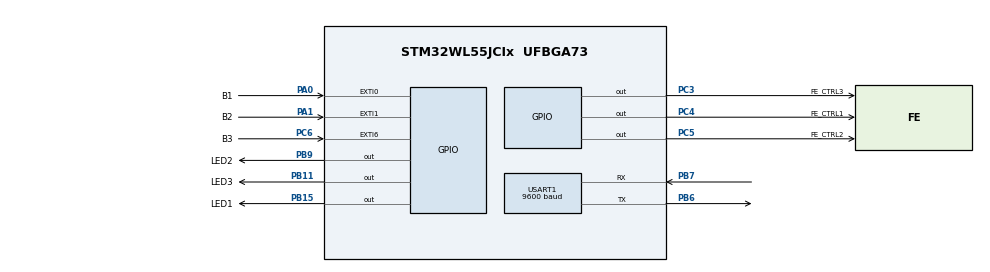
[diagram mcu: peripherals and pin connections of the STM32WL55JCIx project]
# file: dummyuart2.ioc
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Mcu.Family=STM32WL
Mcu.Name=STM32WL55JCIx
Mcu.Package=UFBGA73
NVIC.PriorityGroup=NVIC_PRIORITYGROUP_4
NVIC.USART1_IRQn=true\:0\:0\:false\:false\:true\:true\:true\:true
PA0.GPIO_Label=B1
PA0.GPIO_ModeDefaultEXTI=GPIO_MODE_IT_FALLING
PA0.GPIO_PuPd=GPIO_PULLUP
PA0.Signal=GPXTI0
PA1.GPIO_Label=B2
PA1.GPIO_ModeDefaultEXTI=GPIO_MODE_IT_FALLING
PA1.GPIO_PuPd=GPIO_PULLUP
PA1.Signal=GPXTI1
PA2.GPIO_Label=T_VCP_RX
PA2.Signal=USART2_TX
PA3.GPIO_Label=T_VCP_RX
PA3.Signal=USART2_RX
PB11.GPIO_Label=LED3
PB11.GPIO_Speed=GPIO_SPEED_FREQ_HIGH
PB11.Signal=GPIO_Output
PB15.GPIO_Label=LED1
PB15.GPIO_Speed=GPIO_SPEED_FREQ_HIGH
PB15.Signal=GPIO_Output
PB6.GPIO_ModeDefaultPP=GPIO_MODE_AF_OD
PB6.Mode=Asynchronous
PB6.Signal=USART1_TX
PB7.GPIO_ModeDefaultPP=GPIO_MODE_AF_OD
PB7.Mode=Asynchronous
PB7.Signal=USART1_RX
PB9.GPIO_FM9=__NULL
PB9.GPIO_Label=LED2
PB9.GPIO_Speed=GPIO_SPEED_FREQ_HIGH
PB9.Signal=GPIO_Output
PC14-OSC32_IN.Signal=RCC_OSC32_IN
PC15-OSC32_OUT.Signal=RCC_OSC32_OUT
PC3.GPIO_Label=FE_CTRL3
PC3.GPIO_Speed=GPIO_SPEED_FREQ_VERY_HIGH
PC3.Signal=GPIO_Output
PC4.GPIO_Label=FE_CTRL1
PC4.GPIO_Speed=GPIO_SPEED_FREQ_VERY_HIGH
PC4.Signal=GPIO_Output
PC5.GPIO_Label=FE_CTRL2
PC5.GPIO_Speed=GPIO_SPEED_FREQ_VERY_HIGH
PC5.Signal=GPIO_Output
PC6.GPIO_Label=B3
PC6.GPIO_ModeDefaultEXTI=GPIO_MODE_IT_FALLING
PC6.GPIO_PuPd=GPIO_PULLUP
PC6.Signal=GPXTI6
ProjectManager.HeapSize=0x200
ProjectManager.StackSize=0x400
ProjectManager.TargetToolchain=STM32CubeIDE
RCC.AHBFreq_Value=32000000
RCC.APB1Freq_Value=32000000
RCC.APB1TimFreq_Value=32000000
RCC.APB2Freq_Value=32000000
RCC.APB2TimFreq_Value=32000000
RCC.APB3Freq_Value=32000000
RCC.CortexFreq_Value=32000000
RCC.HCLKFreq_Value=32000000
RCC.HSE_VALUE=32000000
RCC.HSI_VALUE=16000000
RCC.LSE_VALUE=32768
RCC.MSIClockRange=RCC_MSIRANGE_10
RCC.SYSCLKFreq_VALUE=32000000
RCC.VCOOutputFreq_Value=256000000
USART1.BaudRate=9600
USART1.OneBitSampling=UART_ONE_BIT_SAMPLE_ENABLE
USART1.VirtualMode-Asynchronous=VM_ASYNC
board=NUCLEO-WL55JC2

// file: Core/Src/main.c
/* USER CODE BEGIN Header */
/**
  ******************************************************************************
  * @file           : main.c
  * @brief          : Main program body
  ******************************************************************************
  * @attention
  *
  * Copyright (c) 2022 STMicroelectronics.
  * All rights reserved.
  *
  * This software is licensed under terms that can be found in the LICENSE file
  * in the root directory of this software component.
  * If no LICENSE file comes with this software, it is provided AS-IS.
  *
  ******************************************************************************
  */
/* USER CODE END Header */
#include "main.h"

 UART_HandleTypeDef huart1;

void SystemClock_Config(void);
static void MX_GPIO_Init(void);
static void MX_USART1_UART_Init(void);

/* USER CODE BEGIN 0 */
uint8_t dummymsg[10]={
		 1,2,3,4,5,6,7,8,9,10
 };

uint8_t rxdata[10] = {0};
/* USER CODE END 0 */

int main(void)
{

  /* MCU Configuration--------------------------------------------------------*/

  /* Reset of all peripherals, Initializes the Flash interface and the Systick. */
  HAL_Init();

  /* Configure the system clock */
  SystemClock_Config();

  /* Initialize all configured peripherals */
  MX_GPIO_Init();
  MX_USART1_UART_Init();

  /* Infinite loop */
  while (1)
  {

    /* USER CODE BEGIN 3 */
	 // HAL_UART_Receive_IT(&huart1, rxdata, 10);
	  HAL_GPIO_WritePin(LED2_GPIO_Port, LED2_Pin, GPIO_PIN_SET);
	  HAL_UART_Transmit(&huart1, (uint8_t *)dummymsg, 10, 100);
	  HAL_GPIO_WritePin(LED2_GPIO_Port, LED2_Pin, GPIO_PIN_RESET);
  /* USER CODE END 3 */
}
}

void SystemClock_Config(void)
{
  RCC_OscInitTypeDef RCC_OscInitStruct = {0};
  RCC_ClkInitTypeDef RCC_ClkInitStruct = {0};

  /** Configure the main internal regulator output voltage
  */
  __HAL_PWR_VOLTAGESCALING_CONFIG(PWR_REGULATOR_VOLTAGE_SCALE1);

  /** Initializes the CPU, AHB and APB busses clocks
  */
  RCC_OscInitStruct.OscillatorType = RCC_OSCILLATORTYPE_MSI;
  RCC_OscInitStruct.MSIState = RCC_MSI_ON;
  RCC_OscInitStruct.MSICalibrationValue = RCC_MSICALIBRATION_DEFAULT;
  RCC_OscInitStruct.MSIClockRange = RCC_MSIRANGE_10;
  RCC_OscInitStruct.PLL.PLLState = RCC_PLL_NONE;
  if (HAL_RCC_OscConfig(&RCC_OscInitStruct) != HAL_OK)
  {
    Error_Handler();
  }

  /** Configure the SYSCLKSource, HCLK, PCLK1 and PCLK2 clocks dividers
  */
  RCC_ClkInitStruct.ClockType = RCC_CLOCKTYPE_HCLK3|RCC_CLOCKTYPE_HCLK
                              |RCC_CLOCKTYPE_SYSCLK|RCC_CLOCKTYPE_PCLK1
                              |RCC_CLOCKTYPE_PCLK2;
  RCC_ClkInitStruct.SYSCLKSource = RCC_SYSCLKSOURCE_MSI;
  RCC_ClkInitStruct.AHBCLKDivider = RCC_SYSCLK_DIV1;
  RCC_ClkInitStruct.APB1CLKDivider = RCC_HCLK_DIV1;
  RCC_ClkInitStruct.APB2CLKDivider = RCC_HCLK_DIV1;
  RCC_ClkInitStruct.AHBCLK3Divider = RCC_SYSCLK_DIV1;

  if (HAL_RCC_ClockConfig(&RCC_ClkInitStruct, FLASH_LATENCY_1) != HAL_OK)
  {
    Error_Handler();
  }
}

static void MX_USART1_UART_Init(void)
{

  huart1.Instance = USART1;
  huart1.Init.BaudRate = 9600;
  huart1.Init.WordLength = UART_WORDLENGTH_8B;
  huart1.Init.StopBits = UART_STOPBITS_1;
  huart1.Init.Parity = UART_PARITY_NONE;
  huart1.Init.Mode = UART_MODE_TX_RX;
  huart1.Init.HwFlowCtl = UART_HWCONTROL_NONE;
  huart1.Init.OverSampling = UART_OVERSAMPLING_16;
  huart1.Init.OneBitSampling = UART_ONE_BIT_SAMPLE_ENABLE;
  huart1.Init.ClockPrescaler = UART_PRESCALER_DIV1;
  huart1.AdvancedInit.AdvFeatureInit = UART_ADVFEATURE_NO_INIT;
  if (HAL_UART_Init(&huart1) != HAL_OK)
  {
    Error_Handler();
  }
  if (HAL_UARTEx_SetTxFifoThreshold(&huart1, UART_TXFIFO_THRESHOLD_1_8) != HAL_OK)
  {
    Error_Handler();
  }
  if (HAL_UARTEx_SetRxFifoThreshold(&huart1, UART_RXFIFO_THRESHOLD_1_8) != HAL_OK)
  {
    Error_Handler();
  }
  if (HAL_UARTEx_DisableFifoMode(&huart1) != HAL_OK)
  {
    Error_Handler();
  }

}

static void MX_GPIO_Init(void)
{
  GPIO_InitTypeDef GPIO_InitStruct = {0};

  /* GPIO Ports Clock Enable */
  __HAL_RCC_GPIOB_CLK_ENABLE();
  __HAL_RCC_GPIOC_CLK_ENABLE();
  __HAL_RCC_GPIOA_CLK_ENABLE();

  /*Configure GPIO pin Output Level */
  HAL_GPIO_WritePin(GPIOB, LED1_Pin|LED2_Pin|LED3_Pin, GPIO_PIN_RESET);

  /*Configure GPIO pin Output Level */
  HAL_GPIO_WritePin(GPIOC, FE_CTRL3_Pin|FE_CTRL2_Pin|FE_CTRL1_Pin, GPIO_PIN_RESET);

  /*Configure GPIO pins : LED1_Pin LED2_Pin LED3_Pin */
  GPIO_InitStruct.Pin = LED1_Pin|LED2_Pin|LED3_Pin;
  GPIO_InitStruct.Mode = GPIO_MODE_OUTPUT_PP;
  GPIO_InitStruct.Pull = GPIO_NOPULL;
  GPIO_InitStruct.Speed = GPIO_SPEED_FREQ_HIGH;
  HAL_GPIO_Init(GPIOB, &GPIO_InitStruct);

  /*Configure GPIO pins : FE_CTRL3_Pin FE_CTRL2_Pin FE_CTRL1_Pin */
  GPIO_InitStruct.Pin = FE_CTRL3_Pin|FE_CTRL2_Pin|FE_CTRL1_Pin;
  GPIO_InitStruct.Mode = GPIO_MODE_OUTPUT_PP;
  GPIO_InitStruct.Pull = GPIO_NOPULL;
  GPIO_InitStruct.Speed = GPIO_SPEED_FREQ_VERY_HIGH;
  HAL_GPIO_Init(GPIOC, &GPIO_InitStruct);

  /*Configure GPIO pins : B1_Pin B2_Pin */
  GPIO_InitStruct.Pin = B1_Pin|B2_Pin;
  GPIO_InitStruct.Mode = GPIO_MODE_IT_FALLING;
  GPIO_InitStruct.Pull = GPIO_PULLUP;
  HAL_GPIO_Init(GPIOA, &GPIO_InitStruct);

  /*Configure GPIO pin : B3_Pin */
  GPIO_InitStruct.Pin = B3_Pin;
  GPIO_InitStruct.Mode = GPIO_MODE_IT_FALLING;
  GPIO_InitStruct.Pull = GPIO_PULLUP;
  HAL_GPIO_Init(B3_GPIO_Port, &GPIO_InitStruct);

  /*Configure GPIO pins : T_VCP_RX_Pin T_VCP_RXA2_Pin */
  GPIO_InitStruct.Pin = T_VCP_RX_Pin|T_VCP_RXA2_Pin;
  GPIO_InitStruct.Mode = GPIO_MODE_AF_PP;
  GPIO_InitStruct.Pull = GPIO_NOPULL;
  GPIO_InitStruct.Speed = GPIO_SPEED_FREQ_LOW;
  GPIO_InitStruct.Alternate = GPIO_AF7_USART2;
  HAL_GPIO_Init(GPIOA, &GPIO_InitStruct);

}

void Error_Handler(void)
{
  __disable_irq();
  while (1)
  {
  }
}
